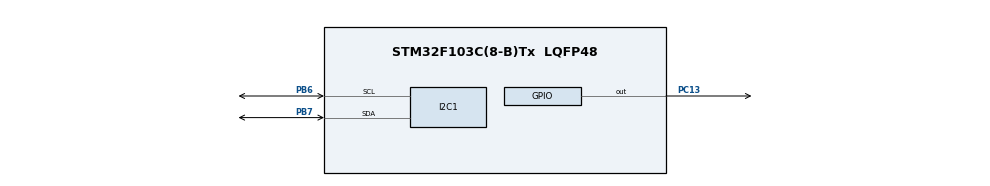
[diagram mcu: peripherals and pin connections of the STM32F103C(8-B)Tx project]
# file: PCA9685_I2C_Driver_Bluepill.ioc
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Mcu.Family=STM32F1
Mcu.Name=STM32F103C(8-B)Tx
Mcu.Package=LQFP48
NVIC.I2C1_ER_IRQn=true\:0\:0\:false\:false\:true\:true\:true
NVIC.I2C1_EV_IRQn=true\:0\:0\:false\:false\:true\:true\:true
NVIC.PriorityGroup=NVIC_PRIORITYGROUP_4
NVIC.TIM2_IRQn=true\:0\:0\:false\:false\:true\:true\:true
PB6.Mode=I2C
PB6.Signal=I2C1_SCL
PB7.Mode=I2C
PB7.Signal=I2C1_SDA
PC13-TAMPER-RTC.Signal=GPIO_Output
ProjectManager.HeapSize=0x200
ProjectManager.StackSize=0x400
ProjectManager.TargetToolchain=STM32CubeIDE
RCC.APB1Freq_Value=8000000
RCC.APB2Freq_Value=8000000
TIM2.Period=122
TIM2.Prescaler=65536-1
VP_SYS_VS_ND.Mode=No_Debug
VP_TIM2_VS_ClockSourceINT.Mode=Internal
board=custom

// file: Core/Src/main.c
/* USER CODE BEGIN Header */
/**
  ******************************************************************************
  * @file           : main.c
  * @brief          : Main program body
  ******************************************************************************
  * @attention
  *
  * <h2><center>&copy; Copyright (c) 2021 STMicroelectronics.
  * All rights reserved.</center></h2>
  *
  * This software component is licensed by ST under BSD 3-Clause license,
  * the "License"; You may not use this file except in compliance with the
  * License. You may obtain a copy of the License at:
  *                        opensource.org/licenses/BSD-3-Clause
  *
  ******************************************************************************
  */
/* USER CODE END Header */
#include "main.h"

I2C_HandleTypeDef hi2c1;

TIM_HandleTypeDef htim2;

void SystemClock_Config(void);
static void MX_GPIO_Init(void);
static void MX_I2C1_Init(void);
static void MX_TIM2_Init(void);

int main(void)
{

  /* MCU Configuration--------------------------------------------------------*/

  /* Reset of all peripherals, Initializes the Flash interface and the Systick. */
  HAL_Init();

  /* Configure the system clock */
  SystemClock_Config();

  /* Initialize all configured peripherals */
  MX_GPIO_Init();
  MX_I2C1_Init();
  MX_TIM2_Init();
  /* USER CODE BEGIN 2 */

  //Start the TIM2 (Interrupts) with max prescaler 35636-1 and 122 counter to get approx 1 sec
  HAL_TIM_Base_Start_IT(&htim2);

  //Use the callback
//  HAL_I2C_MasterTxCpltCallback
  /* USER CODE END 2 */

  /* Infinite loop */
  /* USER CODE BEGIN WHILE */
  while (1)
  {
//	  HAL_GPIO_TogglePin(GPIOC, GPIO_PIN_13);
//	  HAL_Delay(500);
    /* USER CODE END WHILE */

  }
}

void SystemClock_Config(void)
{
  RCC_OscInitTypeDef RCC_OscInitStruct = {0};
  RCC_ClkInitTypeDef RCC_ClkInitStruct = {0};

  /** Initializes the RCC Oscillators according to the specified parameters
  * in the RCC_OscInitTypeDef structure.
  */
  RCC_OscInitStruct.OscillatorType = RCC_OSCILLATORTYPE_HSI;
  RCC_OscInitStruct.HSIState = RCC_HSI_ON;
  RCC_OscInitStruct.HSICalibrationValue = RCC_HSICALIBRATION_DEFAULT;
  RCC_OscInitStruct.PLL.PLLState = RCC_PLL_NONE;
  if (HAL_RCC_OscConfig(&RCC_OscInitStruct) != HAL_OK)
  {
    Error_Handler();
  }
  /** Initializes the CPU, AHB and APB buses clocks
  */
  RCC_ClkInitStruct.ClockType = RCC_CLOCKTYPE_HCLK|RCC_CLOCKTYPE_SYSCLK
                              |RCC_CLOCKTYPE_PCLK1|RCC_CLOCKTYPE_PCLK2;
  RCC_ClkInitStruct.SYSCLKSource = RCC_SYSCLKSOURCE_HSI;
  RCC_ClkInitStruct.AHBCLKDivider = RCC_SYSCLK_DIV1;
  RCC_ClkInitStruct.APB1CLKDivider = RCC_HCLK_DIV1;
  RCC_ClkInitStruct.APB2CLKDivider = RCC_HCLK_DIV1;

  if (HAL_RCC_ClockConfig(&RCC_ClkInitStruct, FLASH_LATENCY_0) != HAL_OK)
  {
    Error_Handler();
  }
}

static void MX_I2C1_Init(void)
{

  hi2c1.Instance = I2C1;
  hi2c1.Init.ClockSpeed = 100000;
  hi2c1.Init.DutyCycle = I2C_DUTYCYCLE_2;
  hi2c1.Init.OwnAddress1 = 0;
  hi2c1.Init.AddressingMode = I2C_ADDRESSINGMODE_7BIT;
  hi2c1.Init.DualAddressMode = I2C_DUALADDRESS_DISABLE;
  hi2c1.Init.OwnAddress2 = 0;
  hi2c1.Init.GeneralCallMode = I2C_GENERALCALL_DISABLE;
  hi2c1.Init.NoStretchMode = I2C_NOSTRETCH_DISABLE;
  if (HAL_I2C_Init(&hi2c1) != HAL_OK)
  {
    Error_Handler();
  }

}

static void MX_TIM2_Init(void)
{

  TIM_ClockConfigTypeDef sClockSourceConfig = {0};
  TIM_MasterConfigTypeDef sMasterConfig = {0};

  htim2.Instance = TIM2;
  htim2.Init.Prescaler = 65536-1;
  htim2.Init.CounterMode = TIM_COUNTERMODE_UP;
  htim2.Init.Period = 122;
  htim2.Init.ClockDivision = TIM_CLOCKDIVISION_DIV1;
  htim2.Init.AutoReloadPreload = TIM_AUTORELOAD_PRELOAD_DISABLE;
  if (HAL_TIM_Base_Init(&htim2) != HAL_OK)
  {
    Error_Handler();
  }
  sClockSourceConfig.ClockSource = TIM_CLOCKSOURCE_INTERNAL;
  if (HAL_TIM_ConfigClockSource(&htim2, &sClockSourceConfig) != HAL_OK)
  {
    Error_Handler();
  }
  sMasterConfig.MasterOutputTrigger = TIM_TRGO_RESET;
  sMasterConfig.MasterSlaveMode = TIM_MASTERSLAVEMODE_DISABLE;
  if (HAL_TIMEx_MasterConfigSynchronization(&htim2, &sMasterConfig) != HAL_OK)
  {
    Error_Handler();
  }

}

static void MX_GPIO_Init(void)
{
  GPIO_InitTypeDef GPIO_InitStruct = {0};

  /* GPIO Ports Clock Enable */
  __HAL_RCC_GPIOC_CLK_ENABLE();
  __HAL_RCC_GPIOB_CLK_ENABLE();

  /*Configure GPIO pin Output Level */
  HAL_GPIO_WritePin(GPIOC, GPIO_PIN_13, GPIO_PIN_RESET);

  /*Configure GPIO pin : PC13 */
  GPIO_InitStruct.Pin = GPIO_PIN_13;
  GPIO_InitStruct.Mode = GPIO_MODE_OUTPUT_PP;
  GPIO_InitStruct.Pull = GPIO_NOPULL;
  GPIO_InitStruct.Speed = GPIO_SPEED_FREQ_LOW;
  HAL_GPIO_Init(GPIOC, &GPIO_InitStruct);

}

/* USER CODE BEGIN 4 */

// Toggle LED PC13 integrated in the Bluepill approx every 1 sec
void HAL_TIM_PeriodElapsedCallback(TIM_HandleTypeDef *htim)
{
	if(htim == &htim2)
	{
//		HAL_GPIO_TogglePin(GPIOC, GPIO_PIN_13);
		HAL_GPIO_WritePin(GPIOC, GPIO_PIN_13, GPIO_PIN_SET);
		//Start I2C1 with interrupts
		// IK, 7b addr, 1b w/r
		uint8_t dev_addr = (0x40<<1)|0x00; // Write
		uint8_t led0_ON_L_addr = 0x06;
		uint8_t led0_ON_H_addr = 0x07;
		uint8_t led0_OFF_L_addr = 0x08;
		uint8_t led0_OFF_H_addr = 0x09;

		uint8_t led0_ON_H_dc = 0x01;
		uint8_t led0_ON_L_dc = 0x99;
		uint8_t led0_OFF_H_dc = 0x04;
		uint8_t led0_OFF_L_dc = 0xCC;

		uint8_t i2c_buff[] = {
				led0_ON_L_addr, led0_ON_L_dc, led0_ON_H_addr, led0_ON_H_dc,
				led0_OFF_L_addr, led0_OFF_L_dc, led0_OFF_H_addr, led0_OFF_H_dc
		};

		HAL_I2C_Master_Transmit_IT(&hi2c1,dev_addr, i2c_buff, 2);
		HAL_GPIO_WritePin(GPIOC, GPIO_PIN_13, GPIO_PIN_RESET);
	}
}

//void HAL_I2C_MasterTxCpltCallback(I2C_HandleTypeDef *hi2c)
//{
//	if(hi2c == &hi2c1)
//	{
//
//	}
//}

/* USER CODE END 4 */

void Error_Handler(void)
{
  __disable_irq();
  while (1)
  {
  }
}

/************************ (C) COPYRIGHT STMicroelectronics *****END OF FILE****/
